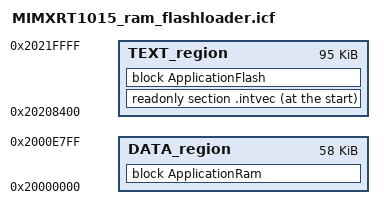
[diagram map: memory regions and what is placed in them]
/*
** ###################################################################
**     Processors:          MIMXRT1015CAF4A
**                          MIMXRT1015DAF5A
**
**     Compiler:            IAR ANSI C/C++ Compiler for ARM
**     Reference manual:    IMXRT1015RM Rev. 1RC, 05/2018
**     Version:             rev. 0.1, 2018-11-05
**     Build:               b181107
**
**     Abstract:
**         Linker file for the IAR ANSI C/C++ Compiler for ARM
**
**     Copyright 2016 Freescale Semiconductor, Inc.
**     Copyright 2016-2018 NXP
**     All rights reserved.
**
**     SPDX-License-Identifier: BSD-3-Clause
**
**     http:                 www.nxp.com
**     mail:                 support@nxp.com
**
** ###################################################################
*/
define symbol m_text_start             = 0x20208400;
define symbol m_text_end               = 0x2021FFFF;

define symbol m_data_start             = 0x20000000;
define symbol m_data_end               = 0x2000FFFF;

/* Sizes */
if (isdefinedsymbol(__stack_size__)) {
  define symbol __size_cstack__        = __stack_size__;
} else {
  define symbol __size_cstack__        = 0x1800;
}

if (isdefinedsymbol(__heap_size__)) {
  define symbol __size_heap__          = __heap_size__;
} else {
  define symbol __size_heap__          = 0x0;
}

define exported symbol __RAM_VECTOR_TABLE_SIZE = 0x0;

define memory mem with size = 4G;
define region TEXT_region = mem:[from m_text_start to m_text_end];
define region DATA_region = mem:[from m_data_start to m_data_end-__size_cstack__];

define block CSTACK    with alignment = 8, size = __size_cstack__   { };
define block HEAP      with alignment = 8, size = __size_heap__     { };

initialize by copy { readwrite };
initialize by copy { section .data};
initialize by copy { section .textrw };
do not initialize  { section .noinit };

define block USBGlobal {section m_usb_bdt, section m_usb_global};
define block CodeRelocate { section .textrw_init };
define block CodeRelocateRam { section .textrw };
define block ApplicationFlash { readonly, block CodeRelocate, readonly section .noinit };
define block ApplicationRam { block USBGlobal, readwrite, block CodeRelocateRam, block CSTACK, block HEAP };
place at start of TEXT_region    { readonly section .intvec };
place in TEXT_region { block ApplicationFlash };
place in DATA_region { block ApplicationRam };

